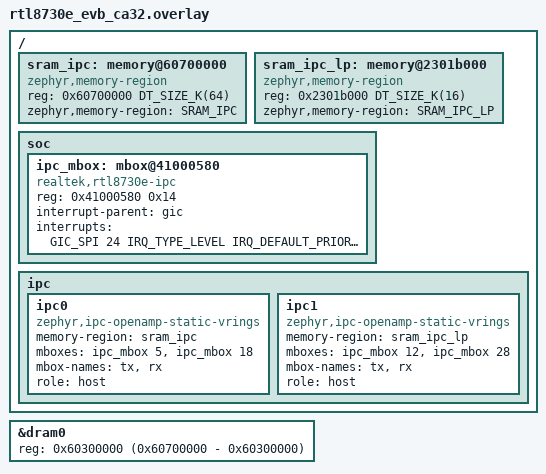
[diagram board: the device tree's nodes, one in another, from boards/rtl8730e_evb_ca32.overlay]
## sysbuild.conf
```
# Sysbuild configuration for the RTL8730E tri-core rpmsg sample.
#
# Build one flashable app.bin that combines all three OUR cores:
#   * CA32 (default image, this sample built for rtl8730e_evb/rtl8730e/ca32) --
#     the rpmsg host; its non-MCUboot image-assembly step (merge_bin.py
#     handle_amebasmart) folds in the KM4 and KM0 image2 sub-images.
#   * KM4  (rtl8730e_evb/rtl8730e/km4)  -- rpmsg remote, packaged image2.
#   * KM0  (rtl8730e_evb/rtl8730e/km0)  -- rpmsg remote, packaged image2.
#
# No MCUboot: the vendor IMG1 (km4_boot_all.bin) stays the bootloader, and the
# CA32 image emits app.bin for the vendor IMG2 slot. Disabling MCUboot is what
# makes the CA32 SOC CMakeLists run handle_amebasmart (the combine path).
SB_CONFIG_BOOTLOADER_NONE=y

# Build the KM4 and KM0 remotes from THIS sample (relative to APP_DIR) for their
# respective core board targets. The board sysbuild.cmake adds them as build-only
# images ordered before the CA32 image so their image2 outputs exist at combine
# time.
SB_CONFIG_RTL8730E_BUILD_KM4_APP=y
SB_CONFIG_RTL8730E_KM4_APP_SOURCE_DIR="."
SB_CONFIG_RTL8730E_BUILD_KM0_APP=y
SB_CONFIG_RTL8730E_KM0_APP_SOURCE_DIR="."
```

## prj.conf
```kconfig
CONFIG_PRINTK=y
CONFIG_LOG=y
CONFIG_IPC_SERVICE_LOG_LEVEL_INF=y

CONFIG_HEAP_MEM_POOL_SIZE=4096

CONFIG_IPC_SERVICE=y
CONFIG_MBOX=y
CONFIG_OPENAMP=y

# The PSRAM / SRAM shared regions retain their contents across a warm reset, so
# every core must zero its vdev status area at init rather than trust stale
# shared state.  This matters most on the REMOTES (KM4/KM0): they boot seconds
# before the CA32 (which waits on TF-A/SMP bring-up), and without the reset they
# read the *previous* run's DRIVER_OK, skip waiting for the host and fire their
# one-shot NS announcement into vrings the host later re-initializes -- the
# announcement is wiped and the endpoint can never bind.  The remote-side reset
# is safe here because the SoC boot flow guarantees the remotes boot (and clear
# the status page at PRE_KERNEL_1) long before the host opens the instances.
# (prj.conf is shared by all three domains; each option only affects instances
# of the matching role, so both are enabled here.)
CONFIG_IPC_SERVICE_BACKEND_RPMSG_SHMEM_RESET=y
CONFIG_IPC_SERVICE_BACKEND_RPMSG_SHMEM_RESET_REMOTE=y

# Cache coherency for the shared vrings is handled by mapping them
# non-cacheable on every core, so OpenAMP does NOT need to perform software
# cache ops (CONFIG_OPENAMP_WITH_DCACHE stays off):
#   * CA32 (host)  -- Normal-Non-cacheable MMU regions REGION_KM4_VRING /
#     REGION_KM0_VRING (soc/.../amebasmart/mmu_regions.c).
#   * KM0 (remote) -- has no D-cache at all.
#   * KM4 (remote) -- has a D-cache and runs from PSRAM, but its vring node
#     (sram_ipc @ 0x60700000) carries zephyr,memory-attr = ATTR_MPU_RAM_NOCACHE,
#     so the arch MPU init (CONFIG_MEM_ATTR) auto-programs it Normal-Non-cacheable
#     from devicetree -- no custom SoC MPU table needed.
# Keeping the default MEM_ALIGNMENT is fine because no core caches the vrings.
```

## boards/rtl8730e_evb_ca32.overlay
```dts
/*
 * Copyright (c) 2026 Realtek Semiconductor Corp.
 *
 * SPDX-License-Identifier: Apache-2.0
 *
 * CA32 (Cortex-A32) = OpenAMP rpmsg HOST for BOTH remotes.
 *
 * IPC block: IPCAP @ 0x41000580 (this core's own doorbell view).  The single
 * block and its single interrupt (GIC SPI 24 / INTID 56) are shared by the two
 * rpmsg instances; each registers its RX callback on a disjoint absolute bit.
 *
 * mbox cells are ABSOLUTE register bits (see realtek,rtl8730e-ipc.yaml):
 *   KM4 link  (AP<->NP): CA32 tx = bit 5  (AP_TO_NP ch5), rx = bit 18 (NP_TO_AP ch2)
 *   KM0 link  (AP<->LP): CA32 tx = bit 12 (AP_TO_LP ch4), rx = bit 28 (LP_TO_AP ch4)
 *
 * Cache coherency: the shared regions are made Normal Non-cacheable on the CA32
 * side by dedicated MMU entries in soc/.../mmu_regions.c (REGION_KM4_VRING /
 * REGION_KM0_VRING), gated on CONFIG_MBOX_REALTEK_AMEBA_IPC.  zephyr,memory-attr
 * is not consumed by the Cortex-A arm_mmu, hence the static table there.
 */

#include <zephyr/dt-bindings/interrupt-controller/arm-gic.h>

/ {
	/*
	 * KM4 shared vring + rpmsg buffer pool: 64 KB at 0x60700000.
	 * Base of KM4_DRAM_HEAP_EXT (ameba_layout.ld, 0x60700000..PSRAM_END
	 * 0x60800000): non-secure PSRAM, addressed identically by CA32 and KM4.
	 * CA32 dram0 is shrunk below so it no longer covers this window.
	 */
	sram_ipc: memory@60700000 {
		compatible = "zephyr,memory-region", "mmio-sram";
		reg = <0x60700000 DT_SIZE_K(64)>;
		zephyr,memory-region = "SRAM_IPC";
	};

	/*
	 * KM0 shared vring: 16 KB at 0x2301B000 in KM0 SRAM.  KM0 (LP domain)
	 * CANNOT reach PSRAM 0x60xxxxxx (its KM0_BD_DRAM is a len-0 sentinel), so
	 * the CA32<->KM0 region must live in the 0x23xxxxxx SRAM both cores share.
	 * CA32 reaches it through REGION_SRAM (0x20000000+512M) and the dedicated
	 * non-cacheable REGION_KM0_VRING MMU entry.
	 */
	sram_ipc_lp: memory@2301b000 {
		compatible = "zephyr,memory-region", "mmio-sram";
		reg = <0x2301b000 DT_SIZE_K(16)>;
		zephyr,memory-region = "SRAM_IPC_LP";
	};

	soc {
		ipc_mbox: mbox@41000580 {
			compatible = "realtek,rtl8730e-ipc";
			reg = <0x41000580 0x14>;
			interrupt-parent = <&gic>;
			interrupts = <GIC_SPI 24 IRQ_TYPE_LEVEL IRQ_DEFAULT_PRIORITY>;
			#mbox-cells = <1>;
			status = "okay";
		};
	};

	ipc {
		#address-cells = <1>;
		#size-cells = <0>;

		ipc0: ipc0 {
			compatible = "zephyr,ipc-openamp-static-vrings";
			memory-region = <&sram_ipc>;
			mboxes = <&ipc_mbox 5>, <&ipc_mbox 18>;
			mbox-names = "tx", "rx";
			role = "host";
			status = "okay";
		};

		ipc1: ipc1 {
			compatible = "zephyr,ipc-openamp-static-vrings";
			memory-region = <&sram_ipc_lp>;
			mboxes = <&ipc_mbox 12>, <&ipc_mbox 28>;
			mbox-names = "tx", "rx";
			role = "host";
			status = "okay";
		};
	};
};

/*
 * Carve the KM4 shared IPC region out of the CA32 application RAM. dram0
 * otherwise spans 0x60300000..0x60800000 (5 MB) and the linker would place
 * .bss/heap on top of the vrings. Shrink it to CA32_BL3_DRAM_NS
 * (0x60300000..0x60700000).  This also makes AMEBASMART_DRAM_END = 0x60700000
 * so REGION_KM4_VRING (0x60700000+64K) does not overlap REGION_DRAM_BEYOND.
 */
&dram0 {
	reg = <0x60300000 (0x60700000 - 0x60300000)>;
};
```

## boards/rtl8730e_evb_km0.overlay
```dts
/*
 * Copyright (c) 2026 Realtek Semiconductor Corp.
 *
 * SPDX-License-Identifier: Apache-2.0
 *
 * KM0 (Real-M200 / Cortex-M23, "LP" core) = OpenAMP rpmsg REMOTE.
 *
 * IPC block: IPCLP @ 0x42008600 (this core's own doorbell view).
 * Interrupt : NVIC IRQ 0 (IPC_LP_IRQ), level triggered.
 *
 * mbox cells are ABSOLUTE register bits (see realtek,rtl8730e-ipc.yaml):
 *   tx = bit 4  (LP_TO_AP ch4, TX shift 0)
 *   rx = bit 20 (AP_TO_LP ch4, RX-full group shift 16 -> 16+4)
 *
 * Shared region: KM0 cannot reach PSRAM (its KM0_BD_DRAM is a len-0 sentinel),
 * so the CA32<->KM0 vring lives in KM0 SRAM at 0x2301B000 (16 KB) -- the only
 * window both CA32 and KM0 physically share.  KM0 (Cortex-M23) has no D-cache,
 * so no cache maintenance is needed on this side; the region is still marked
 * ATTR_MPU_RAM_NOCACHE for an explicit MPU mapping and symmetry with KM4.
 *
 * sram0 (KM0_BD_RAM) is shrunk to 0x23002020..0x2301B000 so the linker never
 * places .bss/heap over the shared window.
 */

#include <zephyr/dt-bindings/memory-attr/memory-attr-arm.h>

/ {
	sram_ipc_lp: memory@2301b000 {
		compatible = "zephyr,memory-region", "mmio-sram";
		reg = <0x2301b000 DT_SIZE_K(16)>;
		zephyr,memory-region = "SRAM_IPC_LP";
		zephyr,memory-attr = <DT_MEM_ARM(ATTR_MPU_RAM_NOCACHE)>;
	};

	soc {
		ipc_mbox: mbox@42008600 {
			compatible = "realtek,rtl8730e-ipc";
			reg = <0x42008600 0x14>;
			interrupt-parent = <&nvic>;
			interrupts = <0 3>;
			#mbox-cells = <1>;
			status = "okay";
		};
	};

	ipc {
		#address-cells = <1>;
		#size-cells = <0>;

		ipc0: ipc0 {
			compatible = "zephyr,ipc-openamp-static-vrings";
			memory-region = <&sram_ipc_lp>;
			mboxes = <&ipc_mbox 4>, <&ipc_mbox 20>;
			mbox-names = "tx", "rx";
			role = "remote";
			status = "okay";
		};
	};
};

/* Reserve the top 16 KB of KM0_BD_RAM for the shared vring window. */
&sram0 {
	reg = <0x23002020 (0x2301b000 - 0x23002020)>;
};
```

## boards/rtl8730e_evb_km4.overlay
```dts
/*
 * Copyright (c) 2026 Realtek Semiconductor Corp.
 *
 * SPDX-License-Identifier: Apache-2.0
 *
 * KM4 (Cortex-M55) = OpenAMP rpmsg REMOTE.
 *
 * IPC block: IPCNP @ 0x41000500 (this core's own doorbell view).
 * Interrupt : NVIC IRQ 24 (IPC_NP_IRQ), level triggered.
 *
 * mbox cells are ABSOLUTE register bits (see realtek,rtl8730e-ipc.yaml):
 *   tx = bit 2  (NP_TO_AP ch2, TX shift 0)
 *   rx = bit 21 (AP_TO_NP ch5, RX-full group shift 16 -> 16+5)
 *
 * The shared region is the same physical address named by the CA32 host
 * (0x60700000, 64 KB, KM4_DRAM_HEAP_EXT). It sits above the KM4 application
 * RAM sram0 (0x60000020..0x6015B000) so no dram shrink is needed here.
 *
 * Cache coherency: KM4 has a D-cache, so the vring region is marked
 * ATTR_MPU_RAM_NOCACHE; mpu_configure_regions_from_dt() programs a
 * non-cacheable MPU region for it at boot.  No CONFIG_OPENAMP_WITH_DCACHE.
 */

#include <zephyr/dt-bindings/memory-attr/memory-attr-arm.h>

/ {
	sram_ipc: memory@60700000 {
		compatible = "zephyr,memory-region", "mmio-sram";
		reg = <0x60700000 DT_SIZE_K(64)>;
		zephyr,memory-region = "SRAM_IPC";
		zephyr,memory-attr = <DT_MEM_ARM(ATTR_MPU_RAM_NOCACHE)>;
	};

	soc {
		ipc_mbox: mbox@41000500 {
			compatible = "realtek,rtl8730e-ipc";
			reg = <0x41000500 0x14>;
			interrupt-parent = <&nvic>;
			interrupts = <24 3>;
			#mbox-cells = <1>;
			status = "okay";
		};
	};

	ipc {
		#address-cells = <1>;
		#size-cells = <0>;

		ipc0: ipc0 {
			compatible = "zephyr,ipc-openamp-static-vrings";
			memory-region = <&sram_ipc>;
			mboxes = <&ipc_mbox 2>, <&ipc_mbox 21>;
			mbox-names = "tx", "rx";
			role = "remote";
			status = "okay";
		};
	};
};
```

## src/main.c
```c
/*
 * Copyright (c) 2026 Realtek Semiconductor Corp.
 *
 * SPDX-License-Identifier: Apache-2.0
 *
 * Minimal OpenAMP rpmsg (ipc_service, static-vrings backend) link test for the
 * RTL8730E.  The CA32 (host) talks to two remotes over two independent rpmsg
 * instances:
 *   - ipc0: CA32 <-> KM4  (shared vrings in PSRAM @ 0x60700000)
 *   - ipc1: CA32 <-> KM0  (shared vrings in KM0 SRAM @ 0x2301B000)
 *
 * The same source is built for all three cores; the host/remote asymmetry and
 * which instance(s) exist live entirely in the device tree.  Each remote board
 * defines only ipc0 (its single link to the host); the CA32 host board defines
 * both.  For every instance present, this app registers an endpoint and, once
 * bound, sends a running counter to the peer and logs what it receives.
 */

#include <zephyr/kernel.h>
#include <zephyr/device.h>
#include <zephyr/ipc/ipc_service.h>
#include <string.h>

#include <zephyr/logging/log.h>
LOG_MODULE_REGISTER(rtl8730e_rpmsg, LOG_LEVEL_INF);

struct link {
	const struct device *dev;
	const char *label;
	struct ipc_ept ep;
	struct ipc_ept_cfg cfg;
	struct k_sem bound_sem;
	uint32_t counter;
};

static void ep_bound(void *priv)
{
	struct link *l = priv;

	k_sem_give(&l->bound_sem);
	LOG_INF("[%s] endpoint bound", l->label);
}

static void ep_recv(const void *data, size_t len, void *priv)
{
	struct link *l = priv;
	uint32_t val = 0;

	memcpy(&val, data, MIN(len, sizeof(val)));
	LOG_INF("[%s] received %zu bytes: %u", l->label, len, val);
}

static void ep_error(const char *message, void *priv)
{
	struct link *l = priv;

	LOG_ERR("[%s] rpmsg error: %s", l->label, message);
}

#define LINK_INITIALIZER(node_id, _label)                                      \
	{                                                                      \
		.dev = DEVICE_DT_GET(node_id),                                 \
		.label = _label,                                               \
	}

static struct link links[] = {
	LINK_INITIALIZER(DT_NODELABEL(ipc0), "ipc0"),
#if DT_NODE_EXISTS(DT_NODELABEL(ipc1))
	LINK_INITIALIZER(DT_NODELABEL(ipc1), "ipc1"),
#endif
};

#define NUM_LINKS ARRAY_SIZE(links)

static int link_setup(struct link *l)
{
	int ret;

	k_sem_init(&l->bound_sem, 0, 1);

	l->cfg.name = "rtl8730e_rpmsg";
	l->cfg.priv = l;
	l->cfg.cb.bound = ep_bound;
	l->cfg.cb.received = ep_recv;
	l->cfg.cb.error = ep_error;

	ret = ipc_service_open_instance(l->dev);
	if ((ret < 0) && (ret != -EALREADY)) {
		LOG_ERR("[%s] ipc_service_open_instance() failed: %d", l->label, ret);
		return ret;
	}

	ret = ipc_service_register_endpoint(l->dev, &l->ep, &l->cfg);
	if (ret < 0) {
		LOG_ERR("[%s] ipc_service_register_endpoint() failed: %d", l->label, ret);
		return ret;
	}

	return 0;
}

int main(void)
{
	LOG_INF("RTL8730E rpmsg sample started (%zu link(s))", NUM_LINKS);

	for (size_t i = 0; i < NUM_LINKS; i++) {
		int ret = link_setup(&links[i]);

		if (ret < 0) {
			return ret;
		}
	}

	/* Wait for every link to bind before starting traffic. */
	for (size_t i = 0; i < NUM_LINKS; i++) {
		k_sem_take(&links[i].bound_sem, K_FOREVER);
	}

	while (1) {
		for (size_t i = 0; i < NUM_LINKS; i++) {
			struct link *l = &links[i];
			int ret = ipc_service_send(&l->ep, &l->counter, sizeof(l->counter));

			if (ret < 0 && ret != -ENOMEM) {
				LOG_ERR("[%s] ipc_service_send() failed: %d", l->label, ret);
			} else if (ret >= 0) {
				LOG_INF("[%s] sent %u", l->label, l->counter);
				l->counter++;
			}
		}
		k_msleep(1000);
	}

	return 0;
}
```
